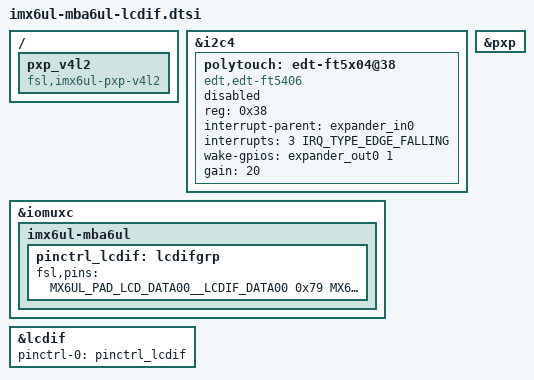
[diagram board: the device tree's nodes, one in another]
/*
 * Copyright 2016 Marco Felsch, TQ Systems GmbH
 * Copyright 2017 Markus Niebel, TQ Systems GmbH
 *
 * The code contained herein is licensed under the GNU General Public
 * License. You may obtain a copy of the GNU General Public License
 * Version 2 or later at the following locations:
 *
 * http://www.opensource.org/licenses/gpl-license.html
 * http://www.gnu.org/copyleft/gpl.html
 */

/ {
	pxp_v4l2 {
		compatible = "fsl,imx6ul-pxp-v4l2", "fsl,imx6sx-pxp-v4l2", "fsl,imx6sl-pxp-v4l2";
		status = "okay";
	};
};

&i2c4 {
	polytouch: edt-ft5x04@38 {
		compatible = "edt,edt-ft5406", "edt,edt-ft5x06";
		reg = <0x38>;
		interrupt-parent = <&expander_in0>;
		interrupts = <3 IRQ_TYPE_EDGE_FALLING>;
		wake-gpios = <&expander_out0 1 GPIO_ACTIVE_HIGH>;
		/* reset-gpios is controlled by stk reset */
		gain = <20>;
		status = "disabled";
	};
};

&iomuxc {
	imx6ul-mba6ul {
		pinctrl_lcdif: lcdifgrp {
			fsl,pins = <
				MX6UL_PAD_LCD_DATA00__LCDIF_DATA00	0x79
				MX6UL_PAD_LCD_DATA01__LCDIF_DATA01	0x79
				MX6UL_PAD_LCD_DATA02__LCDIF_DATA02	0x79
				MX6UL_PAD_LCD_DATA03__LCDIF_DATA03	0x79
				MX6UL_PAD_LCD_DATA04__LCDIF_DATA04	0x79
				MX6UL_PAD_LCD_DATA05__LCDIF_DATA05	0x79
				MX6UL_PAD_LCD_DATA06__LCDIF_DATA06	0x79
				MX6UL_PAD_LCD_DATA07__LCDIF_DATA07	0x79
				MX6UL_PAD_LCD_DATA08__LCDIF_DATA08	0x79
				MX6UL_PAD_LCD_DATA09__LCDIF_DATA09	0x79
				MX6UL_PAD_LCD_DATA10__LCDIF_DATA10	0x79
				MX6UL_PAD_LCD_DATA11__LCDIF_DATA11	0x79
				MX6UL_PAD_LCD_DATA12__LCDIF_DATA12	0x79
				MX6UL_PAD_LCD_DATA13__LCDIF_DATA13	0x79
				MX6UL_PAD_LCD_DATA14__LCDIF_DATA14	0x79
				MX6UL_PAD_LCD_DATA15__LCDIF_DATA15	0x79
				MX6UL_PAD_LCD_DATA16__LCDIF_DATA16	0x79
				MX6UL_PAD_LCD_DATA17__LCDIF_DATA17	0x79
				MX6UL_PAD_LCD_DATA18__LCDIF_DATA18	0x79
				MX6UL_PAD_LCD_DATA19__LCDIF_DATA19	0x79
				MX6UL_PAD_LCD_DATA20__LCDIF_DATA20	0x79
				MX6UL_PAD_LCD_DATA21__LCDIF_DATA21	0x79
				MX6UL_PAD_LCD_DATA22__LCDIF_DATA22	0x79
				MX6UL_PAD_LCD_DATA23__LCDIF_DATA23	0x79

				MX6UL_PAD_LCD_CLK__LCDIF_CLK		0x79
				MX6UL_PAD_LCD_ENABLE__LCDIF_ENABLE	0x79
				MX6UL_PAD_LCD_HSYNC__LCDIF_HSYNC	0x79
				MX6UL_PAD_LCD_VSYNC__LCDIF_VSYNC	0x79
				/* lcd reset */
				/* place r2021, resolder r2022 and comment out */
				/* MX6UL_PAD_LCD_RESET__GPIO3_IO04	0x79 */
			>;
		};
	};
};

&lcdif {
	pinctrl-names = "default";
	pinctrl-0 = <&pinctrl_lcdif>;
	status = "okay";
};

&pxp {
	status = "okay";
};
